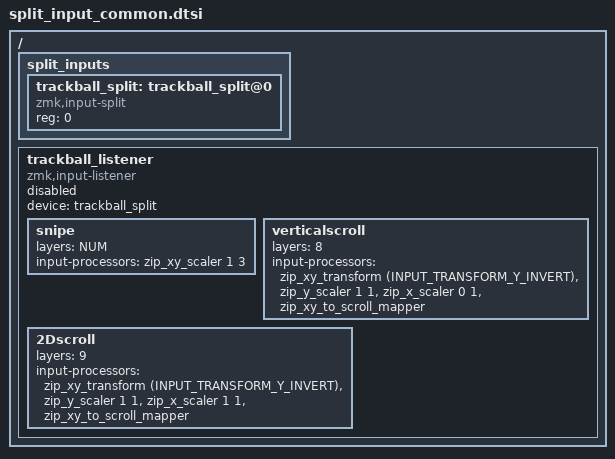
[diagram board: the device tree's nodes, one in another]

#include <dt-bindings/zmk/input_transform.h>
#include <input/processors.dtsi>

#define ZMK_POINTING_DEFAULT_SCRL_VAL 1    // default: 10
#include <dt-bindings/zmk/pointing.h>

#define GAME  1
#define FN    2
#define NUM   3
#define MOUSE 4
#define NAV   5 

/ {
  split_inputs {
    #address-cells = <1>;
    #size-cells = <0>;

    trackball_split: trackball_split@0 {
      compatible = "zmk,input-split";
      reg = <0>;
    };
  };

  trackball_listener: trackball_listener {
    compatible = "zmk,input-listener";
    status = "disabled";
    device = <&trackball_split>;

    snipe {
      layers = <NUM>;
      input-processors = <&zip_xy_scaler 1 3>;
    };

    verticalscroll {
      layers = <8>;
      input-processors = <&zip_xy_transform (INPUT_TRANSFORM_Y_INVERT)>, <&zip_y_scaler 1 1>, <&zip_x_scaler 0 1>, <&zip_xy_to_scroll_mapper>; // скейлер это множитель и делитель скролла
      
    };
    // horizonscroll {
    //  layers = <9>;
    //  input-processors = <&zip_xy_transform (INPUT_TRANSFORM_Y_INVERT)>, <&zip_y_scaler 0 1>, <&zip_x_scaler 1 1>, <&zip_xy_to_scroll_mapper>; // скейлер это множитель и делитель скролла
     
     2Dscroll {
      layers = <9>;
      input-processors = <&zip_xy_transform (INPUT_TRANSFORM_Y_INVERT)>, <&zip_y_scaler 1 1>, <&zip_x_scaler 1 1>, <&zip_xy_to_scroll_mapper>; // скейлер это множитель и делитель скролла
      
    };

//     move {  // автомауслеер
//     layers = <0>; // слои в которых активен автомауслеер 
//     input-processors = <&auto_mouse_layer MOUSE 1000>; // видимо время активности слоя после остановки шара
//     }; // автомауслеер
//  };

//  auto_mouse_layer: auto_mouse_layer {   // автомауслеер
//   compatible = "zmk,input-processor-temp-layer";   // автомауслеер
//  #input-processor-cells = <2>;   // ?
//   require-prior-idle-ms = <500>; // время деактивации слоя после остановки шара
//  #excluded-positions = <20 21 22 23 24 25 26 27 28 29>;   // ?
  };
};
